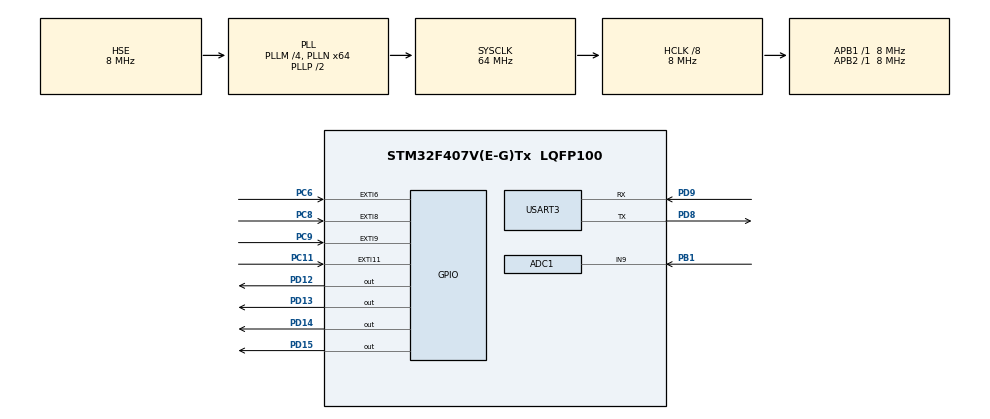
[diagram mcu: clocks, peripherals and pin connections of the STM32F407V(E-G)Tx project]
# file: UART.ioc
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ADC1.Channel-0\#ChannelRegularConversion=ADC_CHANNEL_9
ADC1.ClockPrescaler=ADC_CLOCK_SYNC_PCLK_DIV2
ADC1.ContinuousConvMode=ENABLE
ADC1.DMAContinuousRequests=DISABLE
ADC1.InjNumberOfConversion=0
ADC1.NbrOfConversionFlag=1
ADC1.Rank-0\#ChannelRegularConversion=1
ADC1.SamplingTime-0\#ChannelRegularConversion=ADC_SAMPLETIME_480CYCLES
ADC1.ScanConvMode=DISABLE
ADC1.master=1
Mcu.Family=STM32F4
Mcu.Name=STM32F407V(E-G)Tx
Mcu.Package=LQFP100
NVIC.EXTI15_10_IRQn=true\:0\:0\:false\:false\:true\:true\:true
NVIC.EXTI9_5_IRQn=true\:0\:0\:false\:false\:true\:true\:true
NVIC.PriorityGroup=NVIC_PRIORITYGROUP_4
NVIC.TIM1_UP_TIM10_IRQn=true\:0\:0\:false\:false\:true\:true\:true
NVIC.USART3_IRQn=true\:0\:0\:false\:false\:true\:true\:true
PB1.Signal=ADCx_IN9
PC11.Signal=GPXTI11
PC6.Signal=GPXTI6
PC8.Signal=GPXTI8
PC9.Signal=GPXTI9
PD12.Signal=GPIO_Output
PD13.Signal=GPIO_Output
PD14.Signal=GPIO_Output
PD15.Signal=GPIO_Output
PD8.Mode=Asynchronous
PD8.Signal=USART3_TX
PD9.Mode=Asynchronous
PD9.Signal=USART3_RX
PH0-OSC_IN.Mode=HSE-External-Oscillator
PH0-OSC_IN.Signal=RCC_OSC_IN
PH1-OSC_OUT.Mode=HSE-External-Oscillator
PH1-OSC_OUT.Signal=RCC_OSC_OUT
ProjectManager.HeapSize=0x200
ProjectManager.StackSize=0x400
ProjectManager.TargetToolchain=STM32CubeIDE
RCC.48MHZClocksFreq_Value=32000000
RCC.AHBCLKDivider=RCC_SYSCLK_DIV8
RCC.AHBFreq_Value=8000000
RCC.APB1Freq_Value=8000000
RCC.APB1TimFreq_Value=8000000
RCC.APB2Freq_Value=8000000
RCC.APB2TimFreq_Value=8000000
RCC.CortexFreq_Value=8000000
RCC.HCLKFreq_Value=8000000
RCC.HSE_VALUE=8000000
RCC.HSI_VALUE=16000000
RCC.LSE_VALUE=32768
RCC.PLLM=4
RCC.PLLN=64
RCC.PLLSourceVirtual=RCC_PLLSOURCE_HSE
RCC.SYSCLKFreq_VALUE=64000000
RCC.SYSCLKSource=RCC_SYSCLKSOURCE_PLLCLK
RCC.VCOOutputFreq_Value=128000000
SH.ADCx_IN9.0=ADC1_IN9,IN9
TIM1.Period=1000-1
TIM1.Prescaler=40000-1
USART3.VirtualMode=VM_ASYNC
VP_TIM1_VS_ClockSourceINT.Mode=Internal
board=custom

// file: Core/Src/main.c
/* USER CODE BEGIN Header */
/**
  ******************************************************************************
  * @file           : main.c
  * @brief          : Main program body
  ******************************************************************************
  * @attention
  *
  * <h2><center>&copy; Copyright (c) 2021 STMicroelectronics.
  * All rights reserved.</center></h2>
  *
  * This software component is licensed by ST under BSD 3-Clause license,
  * the "License"; You may not use this file except in compliance with the
  * License. You may obtain a copy of the License at:
  *                        opensource.org/licenses/BSD-3-Clause
  *
  ******************************************************************************
  */
/* USER CODE END Header */
#include "main.h"
#include "adc.h"
#include "tim.h"
#include "usart.h"
#include "gpio.h"

/* USER CODE BEGIN PV */
extern char RX[1];
extern uint16_t ADC_RES;
/* USER CODE END PV */

void SystemClock_Config(void);

int main(void)
{

  /* MCU Configuration--------------------------------------------------------*/

  /* Reset of all peripherals, Initializes the Flash interface and the Systick. */
  HAL_Init();

  /* Configure the system clock */
  SystemClock_Config();

  /* Initialize all configured peripherals */
  MX_GPIO_Init();
  MX_ADC1_Init();
  MX_USART3_UART_Init();
  MX_TIM1_Init();
  /* USER CODE BEGIN 2 */
  HAL_TIM_Base_Start_IT(&htim1);
  HAL_UART_Receive_IT(&huart3, (uint8_t *)RX,1);												//First start of uart receive
  /* USER CODE END 2 */

  /* Infinite loop */
  while (1)
  {

  }
}

void SystemClock_Config(void)
{
  RCC_OscInitTypeDef RCC_OscInitStruct = {0};
  RCC_ClkInitTypeDef RCC_ClkInitStruct = {0};

  /** Configure the main internal regulator output voltage
  */
  __HAL_RCC_PWR_CLK_ENABLE();
  __HAL_PWR_VOLTAGESCALING_CONFIG(PWR_REGULATOR_VOLTAGE_SCALE1);
  /** Initializes the RCC Oscillators according to the specified parameters
  * in the RCC_OscInitTypeDef structure.
  */
  RCC_OscInitStruct.OscillatorType = RCC_OSCILLATORTYPE_HSE;
  RCC_OscInitStruct.HSEState = RCC_HSE_ON;
  RCC_OscInitStruct.PLL.PLLState = RCC_PLL_ON;
  RCC_OscInitStruct.PLL.PLLSource = RCC_PLLSOURCE_HSE;
  RCC_OscInitStruct.PLL.PLLM = 4;
  RCC_OscInitStruct.PLL.PLLN = 64;
  RCC_OscInitStruct.PLL.PLLP = RCC_PLLP_DIV2;
  RCC_OscInitStruct.PLL.PLLQ = 4;
  if (HAL_RCC_OscConfig(&RCC_OscInitStruct) != HAL_OK)
  {
    Error_Handler();
  }
  /** Initializes the CPU, AHB and APB buses clocks
  */
  RCC_ClkInitStruct.ClockType = RCC_CLOCKTYPE_HCLK|RCC_CLOCKTYPE_SYSCLK
                              |RCC_CLOCKTYPE_PCLK1|RCC_CLOCKTYPE_PCLK2;
  RCC_ClkInitStruct.SYSCLKSource = RCC_SYSCLKSOURCE_PLLCLK;
  RCC_ClkInitStruct.AHBCLKDivider = RCC_SYSCLK_DIV8;
  RCC_ClkInitStruct.APB1CLKDivider = RCC_HCLK_DIV1;
  RCC_ClkInitStruct.APB2CLKDivider = RCC_HCLK_DIV1;

  if (HAL_RCC_ClockConfig(&RCC_ClkInitStruct, FLASH_LATENCY_0) != HAL_OK)
  {
    Error_Handler();
  }
}

void Error_Handler(void)
{
  __disable_irq();
  while (1)
  {
  }
}

/************************ (C) COPYRIGHT STMicroelectronics *****END OF FILE****/
